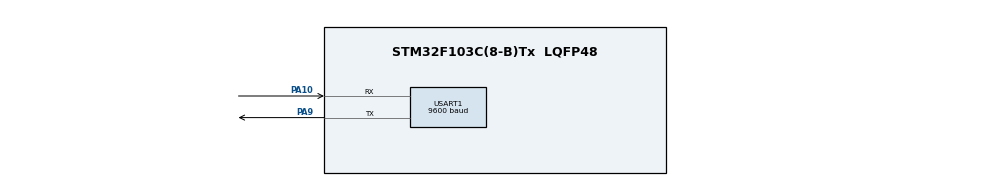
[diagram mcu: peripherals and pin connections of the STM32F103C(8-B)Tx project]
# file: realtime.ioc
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Mcu.Family=STM32F1
Mcu.Name=STM32F103C(8-B)Tx
Mcu.Package=LQFP48
NVIC.PriorityGroup=NVIC_PRIORITYGROUP_4
PA10.Mode=Asynchronous
PA10.Signal=USART1_RX
PA13.Mode=Serial_Wire
PA13.Signal=SYS_JTMS-SWDIO
PA14.Mode=Serial_Wire
PA14.Signal=SYS_JTCK-SWCLK
PA9.Mode=Asynchronous
PA9.Signal=USART1_TX
PC14-OSC32_IN.Mode=LSE-External-Oscillator
PC14-OSC32_IN.Signal=RCC_OSC32_IN
PC15-OSC32_OUT.Mode=LSE-External-Oscillator
PC15-OSC32_OUT.Signal=RCC_OSC32_OUT
PD0-OSC_IN.Mode=HSE-External-Oscillator
PD0-OSC_IN.Signal=RCC_OSC_IN
PD1-OSC_OUT.Mode=HSE-External-Oscillator
PD1-OSC_OUT.Signal=RCC_OSC_OUT
ProjectManager.HeapSize=0x200
ProjectManager.StackSize=0x400
ProjectManager.TargetToolchain=MDK-ARM V5.32
RCC.APB1Freq_Value=8000000
RCC.APB2Freq_Value=8000000
RTC.Date=1
RTC.Hours=4
RTC.Minutes=5
RTC.Month=RTC_MONTH_FEBRUARY
RTC.Seconds=6
RTC.WeekDay=RTC_WEEKDAY_WEDNESDAY
RTC.Year=3
USART1.BaudRate=9600
USART1.VirtualMode=VM_ASYNC
VP_RTC_VS_RTC_Activate.Mode=RTC_Enabled
VP_RTC_VS_RTC_Calendar.Mode=RTC_Calendar
board=custom

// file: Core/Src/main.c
/* USER CODE BEGIN Header */
/**
  ******************************************************************************
  * @file           : main.c
  * @brief          : Main program body
  ******************************************************************************
  * @attention
  *
  * Copyright (c) 2022 STMicroelectronics.
  * All rights reserved.
  *
  * This software is licensed under terms that can be found in the LICENSE file
  * in the root directory of this software component.
  * If no LICENSE file comes with this software, it is provided AS-IS.
  *
  ******************************************************************************
  */
/* USER CODE END Header */
#include "main.h"

RTC_HandleTypeDef hrtc;

UART_HandleTypeDef huart1;

/* USER CODE BEGIN PV */
RTC_TimeTypeDef thoigian;
RTC_DateTypeDef ngaythangnam;
 char time1[100];
 char time2[100];
 char time3[100];
 char date1[30];
 char date2[30];
 char date3[30];
 unsigned char xoa[1];
 unsigned char m[]="Hanoi,\t";
/* USER CODE END PV */

void SystemClock_Config(void);
static void MX_GPIO_Init(void);
static void MX_RTC_Init(void);
static void MX_USART1_UART_Init(void);

int main(void)
{

  /* MCU Configuration--------------------------------------------------------*/

  /* Reset of all peripherals, Initializes the Flash interface and the Systick. */
  HAL_Init();

  /* Configure the system clock */
  SystemClock_Config();

  /* Initialize all configured peripherals */
  MX_GPIO_Init();
  MX_RTC_Init();
  MX_USART1_UART_Init();
  /* USER CODE BEGIN 2 */
xoa[0]=12;
  /* USER CODE END 2 */

  /* Infinite loop */
  /* USER CODE BEGIN WHILE */
  while (1)
  {
		HAL_RTC_GetTime(&hrtc,&thoigian,RTC_FORMAT_BIN);
		HAL_RTC_GetDate(&hrtc,&ngaythangnam,RTC_FORMAT_BIN);

		sprintf(date1,"Ngay %d\t",ngaythangnam.Date);
		sprintf(date2,"Thang %d\t",ngaythangnam.Month);
		sprintf(date3,"Nam %d\t",ngaythangnam.Year);
		sprintf(time1,"Gio %d\t",thoigian.Hours);
		sprintf(time2,"Phut %d\t",thoigian.Minutes);
		sprintf(time3,"Giay %d\t",thoigian.Seconds);
		HAL_UART_Transmit(&huart1,m,15,1000);
		HAL_UART_Transmit(&huart1,(uint8_t *)date1,sizeof(date1),1000);
		HAL_UART_Transmit(&huart1,(uint8_t *)date2,sizeof(date2),1000);
		HAL_UART_Transmit(&huart1,(uint8_t *)date3,sizeof(date3),1000);
		HAL_UART_Transmit(&huart1,(uint8_t *)time1,sizeof(time1),1000);
		HAL_UART_Transmit(&huart1,(uint8_t *)time2,sizeof(time2),1000);
		HAL_UART_Transmit(&huart1,(uint8_t *)time3,sizeof(time3),1000);
		HAL_Delay(1000);
		HAL_UART_Transmit(&huart1,xoa,1,1000);
    /* USER CODE END WHILE */

  }
}

void SystemClock_Config(void)
{
  RCC_OscInitTypeDef RCC_OscInitStruct = {0};
  RCC_ClkInitTypeDef RCC_ClkInitStruct = {0};
  RCC_PeriphCLKInitTypeDef PeriphClkInit = {0};

  /** Initializes the RCC Oscillators according to the specified parameters
  * in the RCC_OscInitTypeDef structure.
  */
  RCC_OscInitStruct.OscillatorType = RCC_OSCILLATORTYPE_HSI|RCC_OSCILLATORTYPE_LSI;
  RCC_OscInitStruct.HSIState = RCC_HSI_ON;
  RCC_OscInitStruct.HSICalibrationValue = RCC_HSICALIBRATION_DEFAULT;
  RCC_OscInitStruct.LSIState = RCC_LSI_ON;
  RCC_OscInitStruct.PLL.PLLState = RCC_PLL_NONE;
  if (HAL_RCC_OscConfig(&RCC_OscInitStruct) != HAL_OK)
  {
    Error_Handler();
  }
  /** Initializes the CPU, AHB and APB buses clocks
  */
  RCC_ClkInitStruct.ClockType = RCC_CLOCKTYPE_HCLK|RCC_CLOCKTYPE_SYSCLK
                              |RCC_CLOCKTYPE_PCLK1|RCC_CLOCKTYPE_PCLK2;
  RCC_ClkInitStruct.SYSCLKSource = RCC_SYSCLKSOURCE_HSI;
  RCC_ClkInitStruct.AHBCLKDivider = RCC_SYSCLK_DIV1;
  RCC_ClkInitStruct.APB1CLKDivider = RCC_HCLK_DIV1;
  RCC_ClkInitStruct.APB2CLKDivider = RCC_HCLK_DIV1;

  if (HAL_RCC_ClockConfig(&RCC_ClkInitStruct, FLASH_LATENCY_0) != HAL_OK)
  {
    Error_Handler();
  }
  PeriphClkInit.PeriphClockSelection = RCC_PERIPHCLK_RTC;
  PeriphClkInit.RTCClockSelection = RCC_RTCCLKSOURCE_LSI;
  if (HAL_RCCEx_PeriphCLKConfig(&PeriphClkInit) != HAL_OK)
  {
    Error_Handler();
  }
}

static void MX_RTC_Init(void)
{

  RTC_TimeTypeDef sTime = {0};
  RTC_DateTypeDef DateToUpdate = {0};

  /** Initialize RTC Only
  */
  hrtc.Instance = RTC;
  hrtc.Init.AsynchPrediv = RTC_AUTO_1_SECOND;
  hrtc.Init.OutPut = RTC_OUTPUTSOURCE_ALARM;
  if (HAL_RTC_Init(&hrtc) != HAL_OK)
  {
    Error_Handler();
  }

  /** Initialize RTC and set the Time and Date
  */
  sTime.Hours = 0x2;
  sTime.Minutes = 0x37;
  sTime.Seconds = 0x40;

  if (HAL_RTC_SetTime(&hrtc, &sTime, RTC_FORMAT_BCD) != HAL_OK)
  {
    Error_Handler();
  }
  DateToUpdate.WeekDay = RTC_WEEKDAY_MONDAY;
  DateToUpdate.Month = RTC_MONTH_OCTOBER;
  DateToUpdate.Date = 0x17;
  DateToUpdate.Year = 0x22;

  if (HAL_RTC_SetDate(&hrtc, &DateToUpdate, RTC_FORMAT_BCD) != HAL_OK)
  {
    Error_Handler();
  }

}

static void MX_USART1_UART_Init(void)
{

  huart1.Instance = USART1;
  huart1.Init.BaudRate = 9600;
  huart1.Init.WordLength = UART_WORDLENGTH_8B;
  huart1.Init.StopBits = UART_STOPBITS_1;
  huart1.Init.Parity = UART_PARITY_NONE;
  huart1.Init.Mode = UART_MODE_TX_RX;
  huart1.Init.HwFlowCtl = UART_HWCONTROL_NONE;
  huart1.Init.OverSampling = UART_OVERSAMPLING_16;
  if (HAL_UART_Init(&huart1) != HAL_OK)
  {
    Error_Handler();
  }

}

static void MX_GPIO_Init(void)
{

  /* GPIO Ports Clock Enable */
  __HAL_RCC_GPIOC_CLK_ENABLE();
  __HAL_RCC_GPIOD_CLK_ENABLE();
  __HAL_RCC_GPIOA_CLK_ENABLE();

}

void Error_Handler(void)
{
  __disable_irq();
  while (1)
  {
  }
}
